AUTOSAR XML (schema 00049)
package /Swcs
  application sw component type asw1
    provide port outPort: provided-interface=srif1
    behavior beh1
      timing event te_5ms: period=0.005, start-on-event=Runnable_1
      runnable-entity symbol=Run1:
        data-send-points:
          access dsp: accessed-variable=outPort.de1
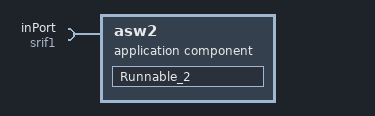
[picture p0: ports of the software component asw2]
  application sw component type asw2
    require port inPort: nonqueued-receiver-com-spec{data-element=de1, enable-update=true, filter={data-filter-type=MASKED-NEW-EQUALS-X, mask=0xfff, max=0b1111, min=04567}}, required-interface=srif1
    behavior beh1
      data received event DRE_Vdp: data=inPort.de1, start-on-event=Runnable_2
      runnable Runnable_2: symbol=Run2
        data-receive-point-by-arguments:
          access dra: accessed-variable=inPort.de1
  composition sw component type Comp
    component asw1_proto: type=asw1
    component asw2_proto: type=asw2
    connect asw1_proto.outPort -> asw2_proto.inPort
  system CanSystem
    system mapping Mappings: sender-receiver-to-signal-mapping{data-element=outPort.de1, system-signal=syssig1}
      sw-mappings:
        swc to ecu mapping SwcMapping: component=rootSwcom.asw1_proto.asw2_proto, ecu-instance=ecu1
    root-software-compositions:
      root sw composition prototype rootSwcom: software-composition=Comp
package /Swcs/Swcs_hierarchy1/Swcs_hierarchy2
  application sw component type asw123
